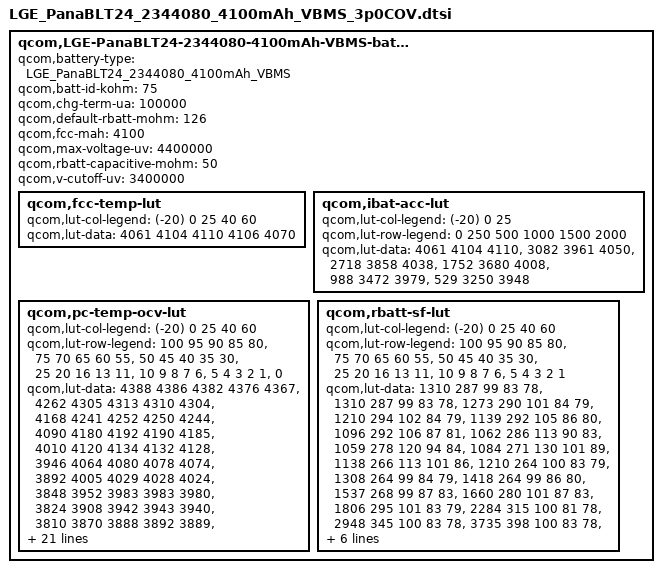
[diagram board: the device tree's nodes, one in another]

qcom,LGE-PanaBLT24-2344080-4100mAh-VBMS-batterydata {
	qcom,battery-type = "LGE_PanaBLT24_2344080_4100mAh_VBMS";
	qcom,batt-id-kohm = <75>;
	qcom,chg-term-ua = <100000>;
	qcom,default-rbatt-mohm = <126>;
	qcom,fcc-mah = <4100>;
	qcom,max-voltage-uv = <4400000>;
	qcom,rbatt-capacitive-mohm = <50>;
	qcom,v-cutoff-uv = <3400000>;

	qcom,fcc-temp-lut {
		qcom,lut-col-legend = <(-20) 0 25 40 60>;
		qcom,lut-data = <4061 4104 4110 4106 4070>;
	};

	qcom,ibat-acc-lut {
		qcom,lut-col-legend = <(-20) 0 25>;
		qcom,lut-row-legend = <0 250 500 1000 1500 2000>;
		qcom,lut-data = <4061 4104 4110>,
				<3082 3961 4050>,
				<2718 3858 4038>,
				<1752 3680 4008>,
				<988 3472 3979>,
				<529 3250 3948>;
	};

	qcom,pc-temp-ocv-lut {
		qcom,lut-col-legend = <(-20) 0 25 40 60>;
		qcom,lut-row-legend = <100 95 90 85 80>,
					<75 70 65 60 55>,
					<50 45 40 35 30>,
					<25 20 16 13 11>,
					<10 9 8 7 6>,
					<5 4 3 2 1>,
					<0>;
		qcom,lut-data = <4388 4386 4382 4376 4367>,
				<4262 4305 4313 4310 4304>,
				<4168 4241 4252 4250 4244>,
				<4090 4180 4192 4190 4185>,
				<4010 4120 4134 4132 4128>,
				<3946 4064 4080 4078 4074>,
				<3892 4005 4029 4028 4024>,
				<3848 3952 3983 3983 3980>,
				<3824 3908 3942 3943 3940>,
				<3810 3870 3888 3892 3889>,
				<3796 3837 3848 3849 3850>,
				<3781 3811 3822 3823 3823>,
				<3764 3789 3802 3804 3803>,
				<3746 3774 3786 3788 3787>,
				<3728 3761 3772 3773 3771>,
				<3707 3744 3761 3756 3745>,
				<3682 3720 3743 3736 3723>,
				<3658 3702 3718 3712 3698>,
				<3636 3688 3692 3684 3674>,
				<3618 3678 3684 3678 3668>,
				<3608 3673 3682 3678 3667>,
				<3600 3666 3681 3676 3666>,
				<3586 3659 3678 3675 3664>,
				<3571 3650 3676 3673 3662>,
				<3557 3639 3671 3668 3656>,
				<3537 3621 3658 3655 3636>,
				<3514 3590 3619 3614 3592>,
				<3486 3542 3554 3551 3528>,
				<3446 3459 3461 3462 3438>,
				<3380 3312 3315 3318 3289>,
				<3000 3000 3000 3000 3000>;
	};

	qcom,rbatt-sf-lut {
		qcom,lut-col-legend = <(-20) 0 25 40 60>;
		qcom,lut-row-legend = <100 95 90 85 80>,
					<75 70 65 60 55>,
					<50 45 40 35 30>,
					<25 20 16 13 11>,
					<10 9 8 7 6>,
					<5 4 3 2 1>;
		qcom,lut-data = <1310 287 99 83 78>,
				<1310 287 99 83 78>,
				<1273 290 101 84 79>,
				<1210 294 102 84 79>,
				<1139 292 105 86 80>,
				<1096 292 106 87 81>,
				<1062 286 113 90 83>,
				<1059 278 120 94 84>,
				<1084 271 130 101 89>,
				<1138 266 113 101 86>,
				<1210 264 100 83 79>,
				<1308 264 99 84 79>,
				<1418 264 99 86 80>,
				<1537 268 99 87 83>,
				<1660 280 101 87 83>,
				<1806 295 101 83 79>,
				<2284 315 100 81 78>,
				<2948 345 100 83 78>,
				<3735 398 100 83 78>,
				<4481 453 102 84 79>,
				<4864 467 102 84 79>,
				<5095 511 103 85 80>,
				<6034 578 105 87 81>,
				<7418 676 109 90 83>,
				<9398 827 114 92 86>,
				<12448 1063 119 92 84>,
				<17862 1506 116 87 82>,
				<29013 2927 121 91 83>,
				<58027 5854 133 95 87>,
				<116054 11708 267 137 144>;
	};
};
